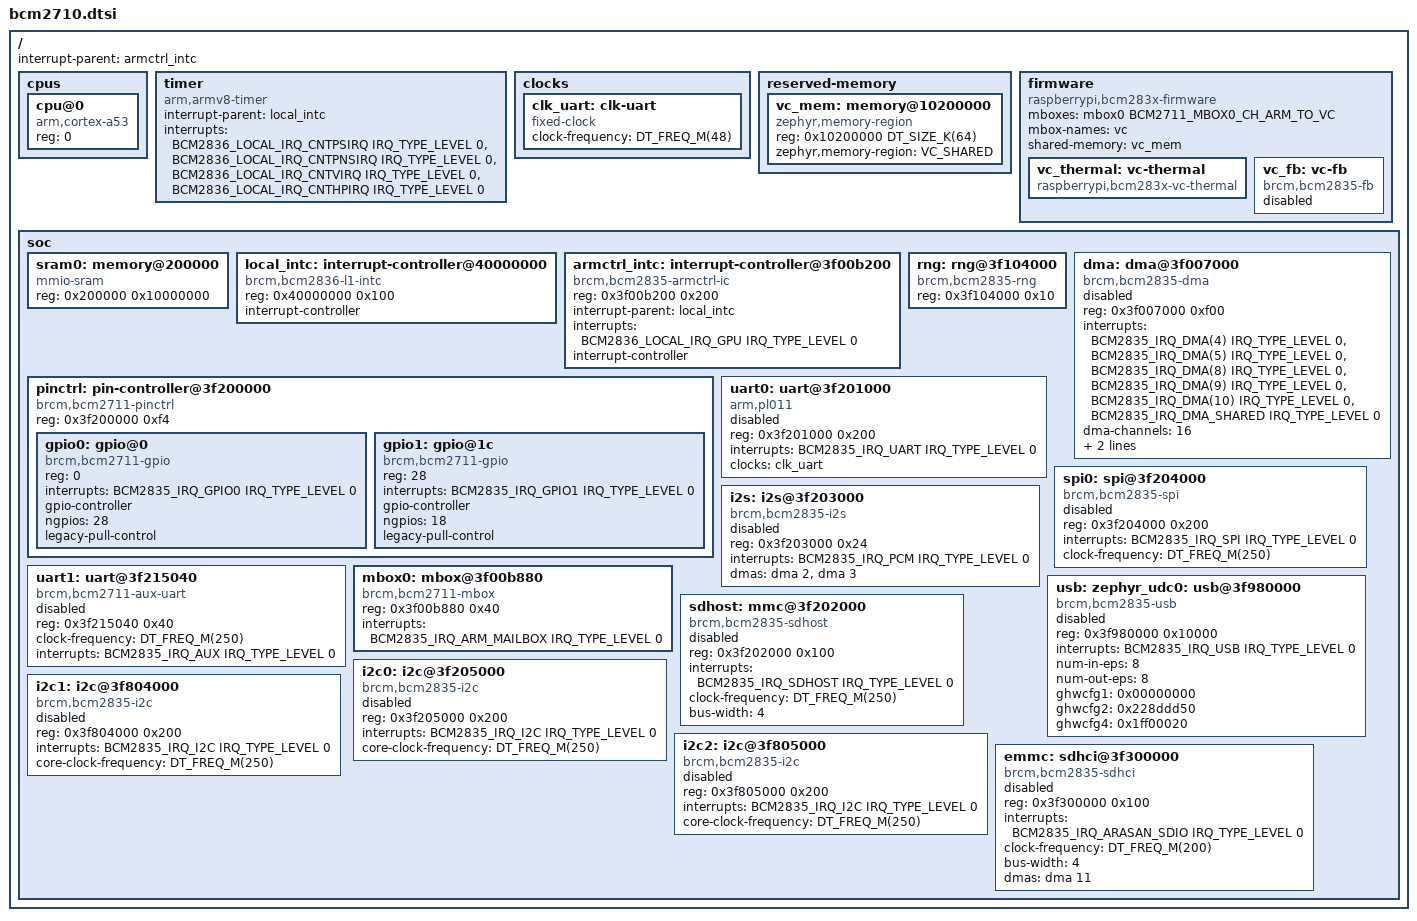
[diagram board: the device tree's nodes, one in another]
/*
 * Copyright (c) 2026 Jonathan Elliot Peace <jep@alphabetiq.com>
 *
 * SPDX-License-Identifier: Apache-2.0
 *
 * Broadcom BCM2710 SoC (Raspberry Pi 3 / Pi Zero 2 W).
 *
 * Interrupts are handled by the native BCM283x controller pair --
 * brcm,bcm2836-l1-intc (per-core timers, mailboxes, PMU and the GPU
 * cascade) and brcm,bcm2835-armctrl-ic (the peripheral aggregator) --
 * driven through the arm64 custom-interrupt-controller hooks in
 * soc/brcm/bcm2710/soc_irq.c.
 */

#include <mem.h>
#include <freq.h>

#include <arm64/armv8-a.dtsi>
#include <zephyr/dt-bindings/interrupt-controller/bcm2836-l1.h>
#include <zephyr/dt-bindings/interrupt-controller/bcm2835-armctrl.h>
#include <zephyr/dt-bindings/mbox/brcm-bcm2711-mbox.h>

/ {
	cpus {
		#address-cells = <1>;
		#size-cells = <0>;

		cpu@0 {
			device_type = "cpu";
			compatible = "arm,cortex-a53";
			reg = <0>;
		};
	};

	interrupt-parent = <&armctrl_intc>;

	timer {
		compatible = "arm,armv8-timer";
		interrupt-parent = <&local_intc>;
		/* 0 = secure phys, 1 = nonsec phys, 2 = virtual, 3 = hyp phys */
		interrupts = <BCM2836_LOCAL_IRQ_CNTPSIRQ  IRQ_TYPE_LEVEL 0>,
			     <BCM2836_LOCAL_IRQ_CNTPNSIRQ IRQ_TYPE_LEVEL 0>,
			     <BCM2836_LOCAL_IRQ_CNTVIRQ   IRQ_TYPE_LEVEL 0>,
			     <BCM2836_LOCAL_IRQ_CNTHPIRQ  IRQ_TYPE_LEVEL 0>;
	};

	clocks {
		clk_uart: clk-uart {
			compatible = "fixed-clock";
			clock-frequency = <DT_FREQ_M(48)>;
			#clock-cells = <0>;
		};
	};

	reserved-memory {
		#address-cells = <1>;
		#size-cells = <1>;
		ranges;

		/*
		 * Shared buffer for the VideoCore firmware property
		 * channel -- just above the kernel DRAM window. The
		 * rpi_fw driver maps it uncached; the VPU reads property
		 * requests from it.
		 */
		vc_mem: memory@10200000 {
			compatible = "zephyr,memory-region";
			reg = <0x10200000 DT_SIZE_K(64)>;
			zephyr,memory-region = "VC_SHARED";
		};
	};

	firmware: firmware {
		compatible = "raspberrypi,bcm283x-firmware";
		mboxes = <&mbox0 BCM2711_MBOX0_CH_ARM_TO_VC>;
		mbox-names = "vc";
		shared-memory = <&vc_mem>;

		vc_thermal: vc-thermal {
			compatible = "raspberrypi,bcm283x-vc-thermal";
			status = "okay";
		};

		/*
		 * VideoCore firmware framebuffer (HDMI). VC owns the HDMI
		 * block, brings up the PHY from config.txt at boot, and
		 * scans this buffer out to the cable continuously; the ARM
		 * side requests the buffer at runtime via the FB property
		 * tags. No width / height here means "ask VC for the EDID
		 * mode". A board or sample overlay opts in.
		 */
		vc_fb: vc-fb {
			compatible = "brcm,bcm2835-fb";
			status = "disabled";
		};
	};

	soc {
		/*
		 * DRAM window the Zephyr image is linked into. Base 0x200000
		 * leaves the bottom 2 MiB free; flashing to hardware needs a
		 * matching kernel_address=0x200000 line in config.txt. The
		 * VPU firmware reserves the top of DRAM, so 256 MiB from
		 * 0x200000 is well within the Pi Zero 2 W's 512 MiB.
		 */
		sram0: memory@200000 {
			device_type = "memory";
			compatible = "mmio-sram";
			reg = <0x200000 0x10000000>;
		};

		local_intc: interrupt-controller@40000000 {
			compatible = "brcm,bcm2836-l1-intc";
			reg = <0x40000000 0x100>;
			interrupt-controller;
			#interrupt-cells = <3>;
			status = "okay";
		};

		armctrl_intc: interrupt-controller@3f00b200 {
			compatible = "brcm,bcm2835-armctrl-ic";
			reg = <0x3f00b200 0x200>;
			interrupt-parent = <&local_intc>;
			interrupts = <BCM2836_LOCAL_IRQ_GPU IRQ_TYPE_LEVEL 0>;
			interrupt-controller;
			#interrupt-cells = <3>;
			status = "okay";
		};

		rng: rng@3f104000 {
			compatible = "brcm,bcm2835-rng";
			reg = <0x3f104000 0x10>;
			status = "okay";
		};

		/*
		 * DMA controller -- a control-block (linked-list
		 * descriptor) engine. Peripherals such as I2S and SPI can
		 * pace transfers off it via DREQ. Default disabled;
		 * boards / test overlays opt in.
		 *
		 * brcm,dma-channel-mask = 0x7f30 keeps channels 4,5,8..14
		 * and excludes the VideoCore-firmware-reserved and
		 * special-function channels (0,1,2,3,6,7). The interrupts
		 * list covers exactly those mask channels: 4,5,8,9,10 have
		 * dedicated lines, 11..14 share one.
		 */
		dma: dma@3f007000 {
			compatible = "brcm,bcm2835-dma";
			reg = <0x3f007000 0xf00>;
			interrupts = <BCM2835_IRQ_DMA(4)  IRQ_TYPE_LEVEL 0>,
				     <BCM2835_IRQ_DMA(5)  IRQ_TYPE_LEVEL 0>,
				     <BCM2835_IRQ_DMA(8)  IRQ_TYPE_LEVEL 0>,
				     <BCM2835_IRQ_DMA(9)  IRQ_TYPE_LEVEL 0>,
				     <BCM2835_IRQ_DMA(10) IRQ_TYPE_LEVEL 0>,
				     <BCM2835_IRQ_DMA_SHARED IRQ_TYPE_LEVEL 0>;
			#dma-cells = <1>;
			dma-channels = <16>;
			brcm,dma-channel-mask = <0x7f30>;
			dma-buf-addr-alignment = <64>;
			status = "disabled";
		};

		pinctrl: pin-controller@3f200000 {
			compatible = "brcm,bcm2711-pinctrl";
			reg = <0x3f200000 0xf4>;
			#address-cells = <1>;
			#size-cells = <0>;

			/*
			 * legacy-pull-control selects the BCM2835-family
			 * GPPUD/GPPUDCLK pull sequence; the BCM2711
			 * PUP_PDN_CNTRL_REG at 0xE4 is reserved on this SoC.
			 */
			gpio0: gpio@0 {
				compatible = "brcm,bcm2711-gpio";
				reg = <0>;
				interrupts = <BCM2835_IRQ_GPIO0 IRQ_TYPE_LEVEL 0>;
				gpio-controller;
				#gpio-cells = <2>;
				ngpios = <28>;
				legacy-pull-control;
				status = "okay";
			};

			gpio1: gpio@1c {
				compatible = "brcm,bcm2711-gpio";
				reg = <28>;
				interrupts = <BCM2835_IRQ_GPIO1 IRQ_TYPE_LEVEL 0>;
				gpio-controller;
				#gpio-cells = <2>;
				ngpios = <18>;
				legacy-pull-control;
				status = "okay";
			};
		};

		uart0: uart@3f201000 {
			compatible = "arm,pl011";
			reg = <0x3f201000 0x200>;
			interrupts = <BCM2835_IRQ_UART IRQ_TYPE_LEVEL 0>;
			interrupt-names = "uart0";
			clocks = <&clk_uart>;
			status = "disabled";
		};

		/*
		 * SPI0 -- the "main" SPI controller on the 40-pin header
		 * (GPIO 7..11, ALT0). Default disabled; boards opt in and
		 * add cs-gpios plus a pinctrl group as needed.
		 *
		 * clock-frequency tracks the VPU core clock, which is
		 * 250 MHz when config.txt sets core_freq=250 -- the same
		 * knob the mini-UART baud divisor already depends on.
		 */
		spi0: spi@3f204000 {
			compatible = "brcm,bcm2835-spi";
			reg = <0x3f204000 0x200>;
			interrupts = <BCM2835_IRQ_SPI IRQ_TYPE_LEVEL 0>;
			clock-frequency = <DT_FREQ_M(250)>;
			#address-cells = <1>;
			#size-cells = <0>;
			status = "disabled";
		};

		i2s: i2s@3f203000 {
			compatible = "brcm,bcm2835-i2s";
			reg = <0x3f203000 0x24>;
			interrupts = <BCM2835_IRQ_PCM IRQ_TYPE_LEVEL 0>;
			dmas = <&dma 2>, <&dma 3>;
			dma-names = "tx", "rx";
			#address-cells = <1>;
			#size-cells = <0>;
			status = "disabled";
		};

		uart1: uart@3f215040 {
			compatible = "brcm,bcm2711-aux-uart";
			reg = <0x3f215040 0x40>;
			clock-frequency = <DT_FREQ_M(250)>;
			interrupts = <BCM2835_IRQ_AUX IRQ_TYPE_LEVEL 0>;
			status = "disabled";
		};

		mbox0: mbox@3f00b880 {
			compatible = "brcm,bcm2711-mbox";
			reg = <0x3f00b880 0x40>;
			interrupts = <BCM2835_IRQ_ARM_MAILBOX IRQ_TYPE_LEVEL 0>;
			#mbox-cells = <1>;
			status = "okay";
		};

		/*
		 * Synopsys DesignWare USB 2.0 OTG controller, wired to the
		 * micro-USB data connector. GHWCFG1/2/4 values are silicon-
		 * fixed and required by snps,dwc2 for endpoint counts and
		 * FIFO topology.
		 */
		usb: zephyr_udc0: usb@3f980000 {
			compatible = "brcm,bcm2835-usb", "snps,dwc2";
			reg = <0x3f980000 0x10000>;
			interrupts = <BCM2835_IRQ_USB IRQ_TYPE_LEVEL 0>;
			num-in-eps = <8>;
			num-out-eps = <8>;
			ghwcfg1 = <0x00000000>;
			ghwcfg2 = <0x228ddd50>;
			ghwcfg4 = <0x1ff00020>;
			status = "disabled";
		};

		/*
		 * Legacy SDHost controller. Drives the external microSD
		 * card slot via GPIO 48..53 at ALT0. Proprietary Broadcom
		 * register layout, distinct from the Arasan SDHCI block
		 * on the same SoC. clock-frequency tracks the VPU core
		 * clock feeding SDHost's SDCDIV reference divider.
		 */
		sdhost: mmc@3f202000 {
			compatible = "brcm,bcm2835-sdhost";
			reg = <0x3f202000 0x100>;
			interrupts = <BCM2835_IRQ_SDHOST IRQ_TYPE_LEVEL 0>;
			clock-frequency = <DT_FREQ_M(250)>;
			bus-width = <4>;
			status = "disabled";
		};

		/*
		 * BSC ("Broadcom Serial Controller") I2C masters. Three
		 * instances on this silicon family: BSC0 lives on the main
		 * peripheral page, BSC1 / BSC2 sit on the secondary page at
		 * 0x3f80x000. Conventionally BSC0 is the HAT-ID-EEPROM bus
		 * (GPIO 0/1, used by the firmware at boot), BSC1 is the
		 * user-facing 40-pin-header bus on GPIO 2/3, and BSC2 is
		 * reserved for HDMI's DDC line and shouldn't be enabled by
		 * application code.
		 *
		 * All three share interrupt line BCM2835_IRQ_I2C -- Linux's
		 * driver declares the same on each node and uses IRQF_SHARED
		 * at request time. With status="disabled" by default only
		 * one will normally be enabled at runtime, so the sharing
		 * doesn't matter in practice; if a board enables more than
		 * one, the build will fail at IRQ_CONNECT-duplicate time,
		 * which is the right place to surface the conflict.
		 *
		 * Default disabled; board / sample overlay opts in.
		 *
		 * core-clock-frequency tracks the VPU core clock that feeds
		 * the BSC CDIV divider, typ. 250 MHz with core_freq=250 in
		 * config.txt. The bus rate is set per-node via the standard
		 * clock-frequency property; the board overlay supplies it.
		 */
		i2c0: i2c@3f205000 {
			compatible = "brcm,bcm2835-i2c";
			reg = <0x3f205000 0x200>;
			interrupts = <BCM2835_IRQ_I2C IRQ_TYPE_LEVEL 0>;
			core-clock-frequency = <DT_FREQ_M(250)>;
			#address-cells = <1>;
			#size-cells = <0>;
			status = "disabled";
		};

		i2c1: i2c@3f804000 {
			compatible = "brcm,bcm2835-i2c";
			reg = <0x3f804000 0x200>;
			interrupts = <BCM2835_IRQ_I2C IRQ_TYPE_LEVEL 0>;
			core-clock-frequency = <DT_FREQ_M(250)>;
			#address-cells = <1>;
			#size-cells = <0>;
			status = "disabled";
		};

		i2c2: i2c@3f805000 {
			compatible = "brcm,bcm2835-i2c";
			reg = <0x3f805000 0x200>;
			interrupts = <BCM2835_IRQ_I2C IRQ_TYPE_LEVEL 0>;
			core-clock-frequency = <DT_FREQ_M(250)>;
			#address-cells = <1>;
			#size-cells = <0>;
			status = "disabled";
		};

		/*
		 * Arasan SDHCI controller (EMMC port). DREQ 11 paces the
		 * external DMA engine that drives the data path; the board
		 * overlay must also enable &dma. Default disabled.
		 */
		emmc: sdhci@3f300000 {
			compatible = "brcm,bcm2835-sdhci";
			reg = <0x3f300000 0x100>;
			interrupts = <BCM2835_IRQ_ARASAN_SDIO IRQ_TYPE_LEVEL 0>;
			clock-frequency = <DT_FREQ_M(200)>;
			bus-width = <4>;
			dmas = <&dma 11>;
			dma-names = "rx-tx";
			status = "disabled";
		};
	};
};
